# haltium_celldsp register map
Vendor: Nordic Semiconductor; Series: nRFHaltium; File version: 1
Registers are 32-bit, read-write, reset 0x0 unless marked. A register's access mark holds for its fields unless they carry their own. Offsets are from the block's base; [hi:lo] are bit positions; lines under a group give offsets from that group; {n}, {i} and the like mark numbered series; 'fields as' and 'values as' point back to an identical list.

## CPUCONF — CPU Configuration
Base 0x45011000
0x00 TASKS_ERASECACHE wo — Erase the caches used by the CPU.
  [0] TASKS_ERASECACHE
    1=Trigger task
0x500 INITSVTOR — Initial value of the secure VTOR (Vector Table Offset Register) after CPU reset.
  [31:0] INITSVTOR — Initial value of the VTOR.
0x504 INITNSVTOR — Initial value of the non-secure VTOR (Vector Table Offset Register).
  [31:0] INITNSVTOR — Initial value of the VTOR.
0x508 CPUSTART — Enable for starting the CPU
  [0] EN — Enable to start the CPU.
    0=Stopped (CPU stopped.); 1=Started (CPU started.)
0x50C CPUWAIT — Enable for the CPU wait.
  [0] EN — Enable to the CPU wait.
    0=Disabled (CPU is not waiting.); 1=Enabled (CPU is waiting.)

## MEMCONF — Memory configuration
Base 0x45012000
{0x500+0x10*i} POWER[{i}] (i=0..3) group — Unspecified
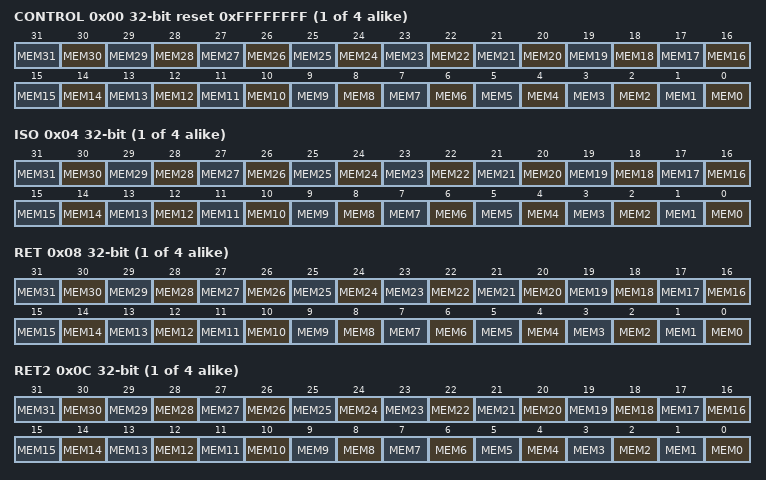
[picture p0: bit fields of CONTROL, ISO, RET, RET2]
  0x00 CONTROL reset 0xFFFFFFFF — Description cluster: RAM/ROM[n] power control register.
    [all] fields
      0=Off (Power down); 1=On (Power up)
    [n] MEM{n} (n=0..31) — Keep the RAM/ROM block MEM[{n}] on or off when in System ON mode.
  0x04 ISO — Description cluster: RAM/ROM [n] power isolation control register.
    [all] fields
      0=Off (Isolation off); 1=On (Isolation on)
    [n] MEM{n} (n=0..31) — Turn on/off the power isolation for RAM/ROM block MEM[{n}].
  0x08 RET — Description cluster: RAM retention for RAM/ROM [n].
    [all] fields
      0=Off (Retention off); 1=On (Retention on)
    [n] MEM{n} (n=0..31) — Keep the RAM block MEM[{n}] retained when in System OFF mode.
  0x0C RET2 — Description cluster: RAM retention for the second bank in the RAM block
    [all] fields
      0=Off (Retention off); 1=On (Retention on)
    [n] MEM{n} (n=0..31) — Keep the second bank in RAM block MEM[{n}] retained when in System OFF mode.
{0x600+0x18*i} REPAIR[{i}] (i=0..31) group — Unspecified
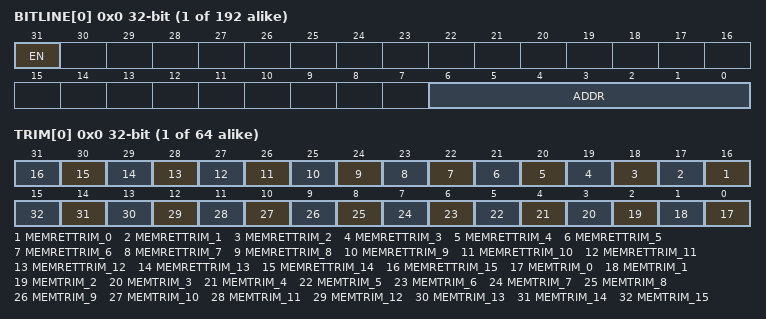
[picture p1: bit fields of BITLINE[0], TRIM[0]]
  {0x0+4j} BITLINE[{j}] (j=0..5) — Description collection: RAM repair bitline configuration RAM/ROM blocks.
    [31] EN — Enable bitline repair
      0=Disabled (Repair disabled.); 1=Enabled (Repair enabled.)
    [6:0] ADDR — Repair address of the bitline
0x900 BLOCKTYPE group — Unspecified
  {0x0+4j} TRIM[{j}] (j=0..63) — Description collection: Trim configuration for the RAM/ROM block types.
    [n+16] MEMRETTRIM_{n} (n=0..15) — Trimming for retention mode for decreased leakage. Must be kept active in RAM retention mode.
    [n] MEMTRIM_{n} (n=0..15) — Read/write margin trim.

## IPCT — IPCT APB registers
Base 0x45013000
{0x0+4i} TASKS_SEND[{i}] (i=0..3) wo — Description collection: Trigger event on IPCT source channel n
  [0] TASKS_SEND — Trigger event on IPCT source channel n
    1=Trigger task
{0x40+4i} TASKS_ACK[{i}] (i=0..3) wo — Description collection: Acknowledge RECEIVE event on IPCT sink channel n
  [0] TASKS_ACK — Acknowledge RECEIVE event on IPCT sink channel n
    1=Trigger task
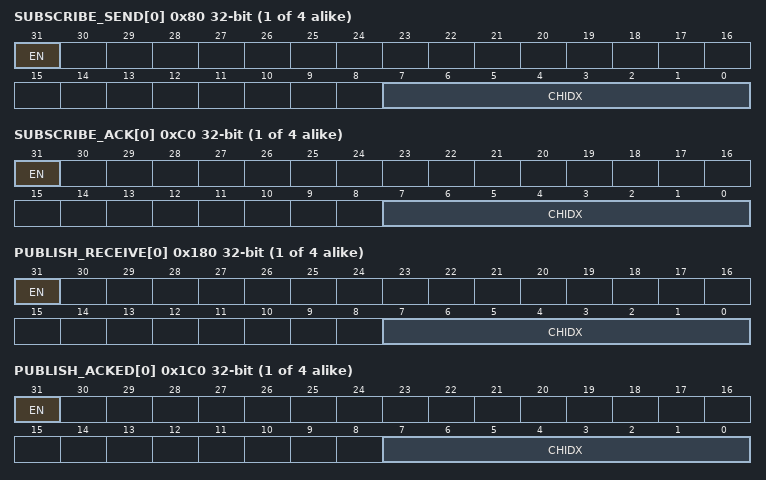
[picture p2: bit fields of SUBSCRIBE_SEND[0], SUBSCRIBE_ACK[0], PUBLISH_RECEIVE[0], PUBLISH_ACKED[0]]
{0x80+4i} SUBSCRIBE_SEND[{i}] (i=0..3) — Description collection: Subscribe configuration for task SEND[n]
  [31] EN
    0=Disabled (Disable subscription); 1=Enabled (Enable subscription)
  [7:0] CHIDX — DPPI channel that task SEND[n] will subscribe to
{0xC0+4i} SUBSCRIBE_ACK[{i}] (i=0..3) — Description collection: Subscribe configuration for task ACK[n]
  [31] EN
    values as SUBSCRIBE_SEND[0].EN
  [7:0] CHIDX — DPPI channel that task ACK[n] will subscribe to
{0x100+4i} EVENTS_RECEIVE[{i}] (i=0..3) — Description collection: Event received on IPCT sink channel n
  [0] EVENTS_RECEIVE — Event received on IPCT sink channel n
    0=NotGenerated (Event not generated); 1=Generated (Event generated)
{0x140+4i} EVENTS_ACKED[{i}] (i=0..3) — Description collection: SEND task on IPCT source channel n was acknowledged
  [0] EVENTS_ACKED — SEND task on IPCT source channel n was acknowledged
    values as EVENTS_RECEIVE[0].EVENTS_RECEIVE
{0x180+4i} PUBLISH_RECEIVE[{i}] (i=0..3) — Description collection: Publish configuration for event RECEIVE[n]
  [31] EN
    0=Disabled (Disable publishing); 1=Enabled (Enable publishing)
  [7:0] CHIDX — DPPI channel that event RECEIVE[n] will publish to
{0x1C0+4i} PUBLISH_ACKED[{i}] (i=0..3) — Description collection: Publish configuration for event ACKED[n]
  [31] EN
    values as PUBLISH_RECEIVE[0].EN
  [7:0] CHIDX — DPPI channel that event ACKED[n] will publish to
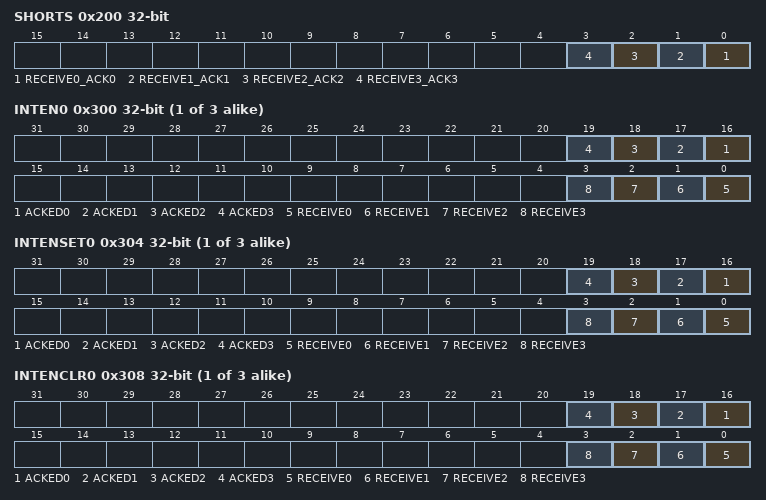
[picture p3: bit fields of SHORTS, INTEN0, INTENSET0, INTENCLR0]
0x200 SHORTS — Shortcuts between local events and tasks
  [all] fields
    0=Disabled (Disable shortcut); 1=Enabled (Enable shortcut)
  [n] RECEIVE{n}_ACK{n} (n=0..3) — Shortcut between event RECEIVE[{n}] and task ACK[{n}]
{0x300+0x10*i} INTEN{i} (i=0..2) — Enable or disable interrupt
  [all] fields
    0=Disabled; 1=Enabled
  [n+16] ACKED{n} (n=0..3) — Enable or disable interrupt for event ACKED[{n}]
  [n] RECEIVE{n} (n=0..3) — Enable or disable interrupt for event RECEIVE[{n}]
{0x304+0x10*i} INTENSET{i} (i=0..2) — Enable interrupt
  [all] fields
    on read: 0=Disabled (Read: Disabled); 1=Enabled (Read: Enabled) | on write: 1=Set (Enable)
  [n+16] ACKED{n} (n=0..3) — Write '1' to enable interrupt for event ACKED[{n}]
  [n] RECEIVE{n} (n=0..3) — Write '1' to enable interrupt for event RECEIVE[{n}]
{0x308+0x10*i} INTENCLR{i} (i=0..2) — Disable interrupt
  [all] fields
    on read: 0=Disabled (Read: Disabled); 1=Enabled (Read: Enabled) | on write: 1=Clear (Disable)
  [n+16] ACKED{n} (n=0..3) — Write '1' to disable interrupt for event ACKED[{n}]
  [n] RECEIVE{n} (n=0..3) — Write '1' to disable interrupt for event RECEIVE[{n}]
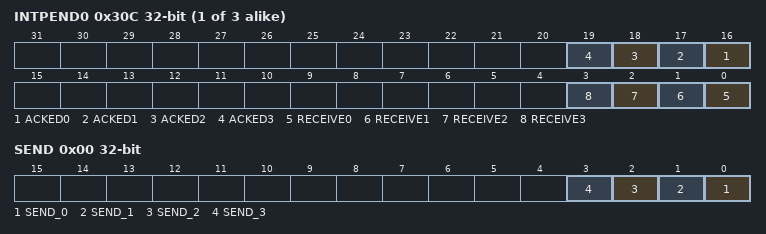
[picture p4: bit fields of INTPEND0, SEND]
{0x30C+0x10*i} INTPEND{i} ro (i=0..2) — Pending interrupts
  [all] fields
    on read: 0=NotPending (Read: Not pending); 1=Pending (Read: Pending)
  [n+16] ACKED{n} (n=0..3) — Read pending status of interrupt for event ACKED[{n}]
  [n] RECEIVE{n} (n=0..3) — Read pending status of interrupt for event RECEIVE[{n}]
0x400 OVERFLOW group — Unspecified
  0x00 SEND — Overflow status for SEND tasks Write 0 to clear
    [all] fields
      1=Overflow (Task overflow has happened); 0=NoOverflow (Task overflow has not happened)
    [n] SEND_{n} (n=0..3) — Overflow status for SEND[{n}] task
